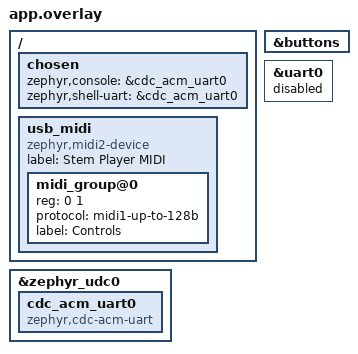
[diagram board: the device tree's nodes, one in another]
/*
 * USB composite device overlay: MIDI 2.0 + CDC ACM serial console.
 * Enables button input drivers for the MIDI controller.
 */

/ {
	chosen {
		zephyr,console = &cdc_acm_uart0;
		zephyr,shell-uart = &cdc_acm_uart0;
	};

	usb_midi: usb_midi {
		compatible = "zephyr,midi2-device";
		status = "okay";
		#address-cells = <1>;
		#size-cells = <1>;
		label = "Stem Player MIDI";

		midi_group@0 {
			reg = <0 1>;
			protocol = "midi1-up-to-128b";
			label = "Controls";
		};
	};
};

/* GPIO Function button input driver (AIN0/AIN1/faders are scanned via bounded NRF_SAADC) */
&buttons {
	status = "okay";
};

&zephyr_udc0 {
	cdc_acm_uart0: cdc_acm_uart0 {
		compatible = "zephyr,cdc-acm-uart";
	};
};

/* Keep unused CYBT Bluetooth UART disabled so we don't drive its lines. */
&uart0 {
	status = "disabled";
};
